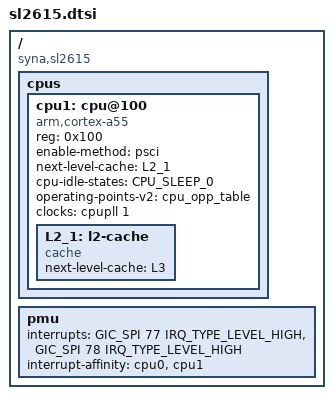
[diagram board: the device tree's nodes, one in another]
// SPDX-License-Identifier: (GPL-2.0 OR MIT)
/*
 * Copyright (C) 2025 Synaptics Incorporated
 *
 * Author: Jisheng Zhang <jszhang@kernel.org>
 */

#include "sl2613.dtsi"

/delete-node/ &csi;
/delete-node/ &isp;
/delete-node/ &camera_video;

/ {
	compatible = "syna,sl2615";

	cpus {
		cpu1: cpu@100 {
			compatible = "arm,cortex-a55";
			device_type = "cpu";
			reg = <0x100>;
			enable-method = "psci";
			next-level-cache = <&L2_1>;
			cpu-idle-states = <&CPU_SLEEP_0>;
			operating-points-v2 = <&cpu_opp_table>;
			clocks = <&cpupll 1>;
			L2_1: l2-cache {
				compatible = "cache";
				next-level-cache = <&L3>;
			};
		};
	};

	pmu {
		interrupts = <GIC_SPI 77 IRQ_TYPE_LEVEL_HIGH>,
			     <GIC_SPI 78 IRQ_TYPE_LEVEL_HIGH>;
		interrupt-affinity = <&cpu0>,
				     <&cpu1>;
	};
};
